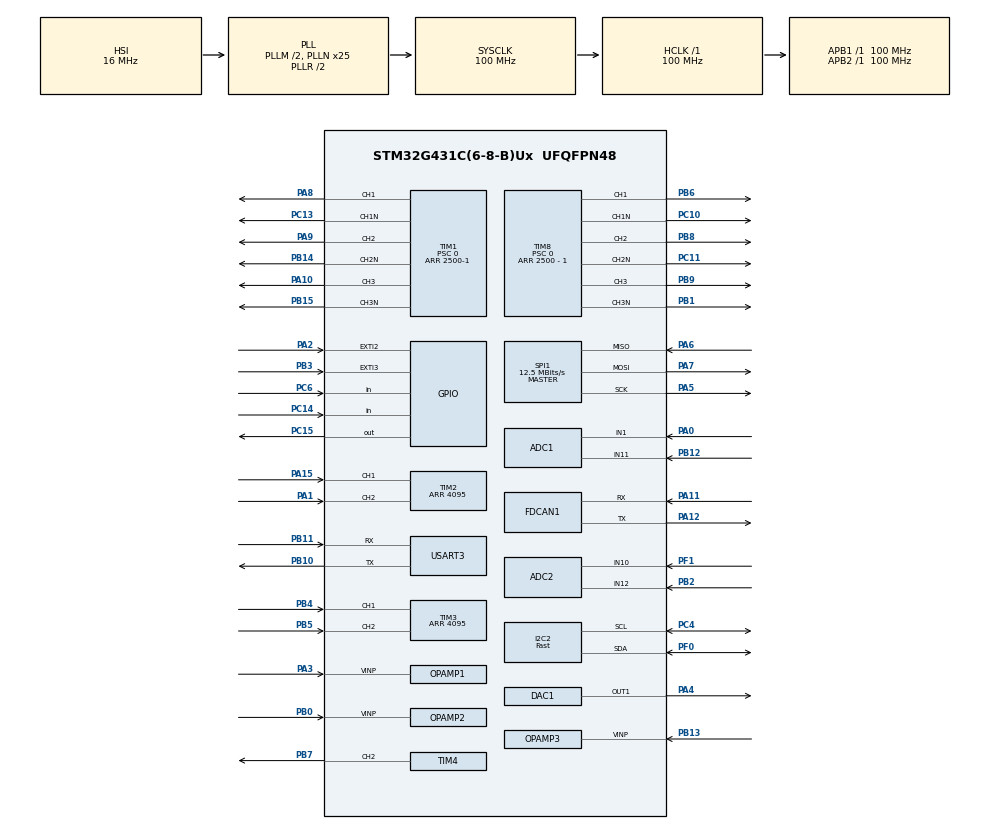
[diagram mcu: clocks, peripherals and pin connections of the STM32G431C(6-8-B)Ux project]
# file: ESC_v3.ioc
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ADC1.EnableInjectedConversion=ENABLE
ADC1.EnableRegularConversion=DISABLE
ADC1.ExternalTrigInjecConv=ADC_EXTERNALTRIGINJEC_T1_TRGO
ADC1.InjNumberOfConversion=1
ADC1.InjectedChannel-1\#ChannelInjectedConversion=ADC_CHANNEL_VOPAMP1
ADC1.InjectedOffsetNumber-1\#ChannelInjectedConversion=ADC_OFFSET_NONE
ADC1.InjectedRank-1\#ChannelInjectedConversion=1
ADC1.InjectedSamplingTime-1\#ChannelInjectedConversion=ADC_SAMPLETIME_2CYCLES_5
ADC1.Mode=ADC_DUALMODE_INJECSIMULT
ADC1.master=1
ADC2.EnableInjectedConversion=ENABLE
ADC2.EnableRegularConversion=DISABLE
ADC2.InjNumberOfConversion=2
ADC2.InjectedChannel-1\#ChannelInjectedConversion=ADC_CHANNEL_VOPAMP2
ADC2.InjectedChannel-2\#ChannelInjectedConversion=ADC_CHANNEL_VOPAMP3_ADC2
ADC2.InjectedOffsetNumber-1\#ChannelInjectedConversion=ADC_OFFSET_NONE
ADC2.InjectedOffsetNumber-2\#ChannelInjectedConversion=ADC_OFFSET_NONE
ADC2.InjectedRank-1\#ChannelInjectedConversion=1
ADC2.InjectedRank-2\#ChannelInjectedConversion=2
ADC2.InjectedSamplingTime-1\#ChannelInjectedConversion=ADC_SAMPLETIME_2CYCLES_5
ADC2.InjectedSamplingTime-2\#ChannelInjectedConversion=ADC_SAMPLETIME_2CYCLES_5
ADC2.Mode=ADC_DUALMODE_INJECSIMULT
Dma.Request0=TIM4_CH2
Dma.Request1=SPI1_TX
Dma.Request2=SPI1_RX
Dma.SPI1_RX.2.Direction=DMA_PERIPH_TO_MEMORY
Dma.SPI1_RX.2.EventEnable=DISABLE
Dma.SPI1_RX.2.Instance=DMA1_Channel3
Dma.SPI1_RX.2.MemDataAlignment=DMA_MDATAALIGN_BYTE
Dma.SPI1_RX.2.MemInc=DMA_MINC_ENABLE
Dma.SPI1_RX.2.Mode=DMA_NORMAL
Dma.SPI1_RX.2.PeriphDataAlignment=DMA_PDATAALIGN_BYTE
Dma.SPI1_RX.2.PeriphInc=DMA_PINC_DISABLE
Dma.SPI1_RX.2.Polarity=HAL_DMAMUX_REQ_GEN_RISING
Dma.SPI1_RX.2.Priority=DMA_PRIORITY_LOW
Dma.SPI1_RX.2.RequestNumber=1
Dma.SPI1_RX.2.SignalID=NONE
Dma.SPI1_RX.2.SyncEnable=DISABLE
Dma.SPI1_RX.2.SyncPolarity=HAL_DMAMUX_SYNC_NO_EVENT
Dma.SPI1_RX.2.SyncRequestNumber=1
Dma.SPI1_RX.2.SyncSignalID=NONE
Dma.SPI1_TX.1.Direction=DMA_MEMORY_TO_PERIPH
Dma.SPI1_TX.1.EventEnable=DISABLE
Dma.SPI1_TX.1.Instance=DMA1_Channel2
Dma.SPI1_TX.1.MemDataAlignment=DMA_MDATAALIGN_BYTE
Dma.SPI1_TX.1.MemInc=DMA_MINC_ENABLE
Dma.SPI1_TX.1.Mode=DMA_NORMAL
Dma.SPI1_TX.1.PeriphDataAlignment=DMA_PDATAALIGN_BYTE
Dma.SPI1_TX.1.PeriphInc=DMA_PINC_DISABLE
Dma.SPI1_TX.1.Polarity=HAL_DMAMUX_REQ_GEN_RISING
Dma.SPI1_TX.1.Priority=DMA_PRIORITY_LOW
Dma.SPI1_TX.1.RequestNumber=1
Dma.SPI1_TX.1.SignalID=NONE
Dma.SPI1_TX.1.SyncEnable=DISABLE
Dma.SPI1_TX.1.SyncPolarity=HAL_DMAMUX_SYNC_NO_EVENT
Dma.SPI1_TX.1.SyncRequestNumber=1
Dma.SPI1_TX.1.SyncSignalID=NONE
Dma.TIM4_CH2.0.Direction=DMA_MEMORY_TO_PERIPH
Dma.TIM4_CH2.0.EventEnable=DISABLE
Dma.TIM4_CH2.0.Instance=DMA1_Channel1
Dma.TIM4_CH2.0.MemDataAlignment=DMA_MDATAALIGN_HALFWORD
Dma.TIM4_CH2.0.MemInc=DMA_MINC_ENABLE
Dma.TIM4_CH2.0.Mode=DMA_NORMAL
Dma.TIM4_CH2.0.PeriphDataAlignment=DMA_PDATAALIGN_HALFWORD
Dma.TIM4_CH2.0.PeriphInc=DMA_PINC_DISABLE
Dma.TIM4_CH2.0.Polarity=HAL_DMAMUX_REQ_GEN_RISING
Dma.TIM4_CH2.0.Priority=DMA_PRIORITY_LOW
Dma.TIM4_CH2.0.RequestNumber=1
Dma.TIM4_CH2.0.SignalID=NONE
Dma.TIM4_CH2.0.SyncEnable=DISABLE
Dma.TIM4_CH2.0.SyncPolarity=HAL_DMAMUX_SYNC_NO_EVENT
Dma.TIM4_CH2.0.SyncRequestNumber=1
Dma.TIM4_CH2.0.SyncSignalID=NONE
FDCAN1.CalculateBaudRateNominal=1000000
FDCAN1.CalculateTimeBitNominal=1000
FDCAN1.CalculateTimeQuantumNominal=10.0
FDCAN1.NominalPrescaler=1
FDCAN1.NominalTimeSeg1=80
FDCAN1.NominalTimeSeg2=19
I2C2.I2C_Speed_Mode=I2C_Fast
I2C2.Timing=0x10911A50
Mcu.Family=STM32G4
Mcu.Name=STM32G431C(6-8-B)Ux
Mcu.Package=UFQFPN48
NVIC.ADC1_2_IRQn=true\:0\:0\:false\:false\:true\:true\:true\:true
NVIC.DMA1_Channel1_IRQn=true\:0\:0\:false\:false\:true\:false\:true\:true
NVIC.DMA1_Channel2_IRQn=true\:0\:0\:false\:false\:true\:false\:true\:true
NVIC.DMA1_Channel3_IRQn=true\:0\:0\:false\:false\:true\:false\:true\:true
NVIC.EXTI2_IRQn=true\:0\:0\:false\:false\:true\:true\:true\:true
NVIC.EXTI3_IRQn=true\:0\:0\:false\:false\:true\:true\:true\:true
NVIC.FMAC_IRQn=true\:0\:0\:false\:false\:true\:true\:true\:true
NVIC.PriorityGroup=NVIC_PRIORITYGROUP_4
NVIC.SPI1_IRQn=true\:0\:0\:false\:false\:true\:true\:true\:true
NVIC.TIM1_UP_TIM16_IRQn=true\:0\:0\:false\:false\:true\:true\:true\:true
NVIC.TIM6_DAC_IRQn=true\:0\:0\:false\:false\:true\:true\:true\:true
NVIC.TIM7_IRQn=true\:0\:0\:false\:false\:true\:true\:true\:true
OPAMP1.PgaGain=OPAMP_PGA_GAIN_32_OR_MINUS_31
OPAMP2.PgaGain=OPAMP_PGA_GAIN_32_OR_MINUS_31
OPAMP3.PgaGain=OPAMP_PGA_GAIN_32_OR_MINUS_31
PA0.Mode=IN1-Single-Ended
PA0.Signal=ADC1_IN1
PA1.Signal=S_TIM2_CH2
PA10.Signal=S_TIM1_CH3
PA11.Mode=FDCAN_Activate
PA11.Signal=FDCAN1_RX
PA12.Mode=FDCAN_Activate
PA12.Signal=FDCAN1_TX
PA13.Mode=Serial_Wire
PA13.Signal=SYS_JTMS-SWDIO
PA14.Mode=Serial_Wire
PA14.Signal=SYS_JTCK-SWCLK
PA15.Signal=S_TIM2_CH1
PA2.Signal=SharedStack_PA2
PA2.Stacked=true
PA3.Mode=PGA_Internally_Connected
PA3.Signal=OPAMP1_VINP
PA4.Signal=COMP_DAC11_group
PA5.Mode=Full_Duplex_Master
PA5.Signal=SPI1_SCK
PA6.Mode=Full_Duplex_Master
PA6.Signal=SPI1_MISO
PA7.Mode=Full_Duplex_Master
PA7.Signal=SPI1_MOSI
PA8.Signal=S_TIM1_CH1
PA9.Signal=S_TIM1_CH2
PB0.Mode=PGA_Internally_Connected
PB0.Signal=OPAMP2_VINP
PB1.Mode=PWM Generation3 CH3 CH3N
PB1.Signal=TIM8_CH3N
PB10.Mode=Asynchronous
PB10.Signal=USART3_TX
PB11.Mode=Asynchronous
PB11.Signal=USART3_RX
PB12.Mode=IN11-Single-Ended
PB12.Signal=ADC1_IN11
PB13.Mode=PGA_Internally_Connected
PB13.Signal=OPAMP3_VINP
PB14.Mode=PWM Generation2 CH2 CH2N
PB14.Signal=TIM1_CH2N
PB15.Mode=PWM Generation3 CH3 CH3N
PB15.Signal=TIM1_CH3N
PB2.Mode=IN12-Single-Ended
PB2.Signal=ADC2_IN12
PB3.Signal=SharedStack_PB3
PB3.Stacked=true
PB4.Signal=SharedStack_PB4
PB4.Stacked=true
PB5.Signal=S_TIM3_CH2
PB5.Stacked=true
PB6.Signal=S_TIM8_CH1
PB7.Signal=S_TIM4_CH2
PB8-BOOT0.Signal=S_TIM8_CH2
PB9.Signal=S_TIM8_CH3
PC10.Mode=PWM Generation1 CH1 CH1N
PC10.Signal=TIM8_CH1N
PC11.Mode=PWM Generation2 CH2 CH2N
PC11.Signal=TIM8_CH2N
PC13.Mode=PWM Generation1 CH1 CH1N
PC13.Signal=TIM1_CH1N
PC14-OSC32_IN.Signal=GPIO_Input
PC15-OSC32_OUT.Signal=GPIO_Output
PC4.Mode=I2C
PC4.Signal=I2C2_SCL
PC6.Signal=GPIO_Input
PF0-OSC_IN.Mode=I2C
PF0-OSC_IN.Signal=I2C2_SDA
PF1-OSC_OUT.Mode=IN10-Single-Ended
PF1-OSC_OUT.Signal=ADC2_IN10
ProjectManager.HeapSize=0x200
ProjectManager.StackSize=0x400
ProjectManager.TargetToolchain=CMake
RCC.ADC12Freq_Value=100000000
RCC.AHBFreq_Value=100000000
RCC.APB1Freq_Value=100000000
RCC.APB1TimFreq_Value=100000000
RCC.APB2Freq_Value=100000000
RCC.APB2TimFreq_Value=100000000
RCC.CortexFreq_Value=100000000
RCC.EXTERNAL_CLOCK_VALUE=12288000
RCC.HCLKFreq_Value=100000000
RCC.HSE_VALUE=8000000
RCC.HSI48_VALUE=48000000
RCC.HSI_VALUE=16000000
RCC.LSE_VALUE=32768
RCC.PLLM=RCC_PLLM_DIV2
RCC.PLLN=25
RCC.SYSCLKFreq_VALUE=100000000
RCC.SYSCLKSource=RCC_SYSCLKSOURCE_PLLCLK
RCC.USBFreq_Value=100000000
RCC.VCOOutputFreq_Value=200000000
SH.COMP_DAC11_group.0=DAC1_OUT1,DAC_OUT1
SH.S_TIM1_CH1.0=TIM1_CH1,PWM Generation1 CH1 CH1N
SH.S_TIM1_CH2.0=TIM1_CH2,PWM Generation2 CH2 CH2N
SH.S_TIM1_CH3.0=TIM1_CH3,PWM Generation3 CH3 CH3N
SH.S_TIM2_CH1.0=TIM2_CH1,Encoder_Interface
SH.S_TIM2_CH2.0=TIM2_CH2,Encoder_Interface
SH.S_TIM3_CH2.0=TIM3_CH2,Encoder_Interface
SH.S_TIM4_CH2.0=TIM4_CH2,PWM Generation2 CH2
SH.S_TIM8_CH1.0=TIM8_CH1,PWM Generation1 CH1 CH1N
SH.S_TIM8_CH2.0=TIM8_CH2,PWM Generation2 CH2 CH2N
SH.S_TIM8_CH3.0=TIM8_CH3,PWM Generation3 CH3 CH3N
SH.SharedStack_PA2.0=TIM2_CH3
SH.SharedStack_PA2.1=GPIO_EXTI2
SH.SharedStack_PB3.0=GPIO_EXTI3
SH.SharedStack_PB3.1=SPI3_SCK
SH.SharedStack_PB4.0=SPI3_MISO
SH.SharedStack_PB4.1=TIM3_CH1,Encoder_Interface
SPI1.BaudRatePrescaler=SPI_BAUDRATEPRESCALER_8
SPI1.CLKPhase=SPI_PHASE_2EDGE
SPI1.CalculateBaudRate=12.5 MBits/s
SPI1.DataSize=SPI_DATASIZE_8BIT
SPI1.Direction=SPI_DIRECTION_2LINES
SPI1.Mode=SPI_MODE_MASTER
SPI1.VirtualType=VM_MASTER
TIM1.Channel-PWM\ Generation1\ CH1\ CH1N=TIM_CHANNEL_1
TIM1.Channel-PWM\ Generation2\ CH2\ CH2N=TIM_CHANNEL_2
TIM1.Channel-PWM\ Generation3\ CH3\ CH3N=TIM_CHANNEL_3
TIM1.CounterMode=TIM_COUNTERMODE_CENTERALIGNED1
TIM1.OCMode_PWM-PWM\ Generation1\ CH1\ CH1N=TIM_OCMODE_PWM2
TIM1.OCMode_PWM-PWM\ Generation2\ CH2\ CH2N=TIM_OCMODE_PWM2
TIM1.OCMode_PWM-PWM\ Generation3\ CH3\ CH3N=TIM_OCMODE_PWM2
TIM1.PeriodNoDither=2500-1
TIM1.Prescaler=0
TIM1.RepetitionCounter=1
TIM1.TIM_MasterOutputTrigger=TIM_TRGO_UPDATE
TIM2.PeriodNoDither=4095
TIM3.PeriodNoDither=4095
TIM4.Channel-PWM\ Generation2\ CH2=TIM_CHANNEL_2
TIM4.PeriodNoDither=149
TIM6.PeriodNoDither=9999
TIM6.Prescaler=9999
TIM7.PeriodNoDither=999
TIM7.Prescaler=9900
TIM8.Channel-PWM\ Generation1\ CH1\ CH1N=TIM_CHANNEL_1
TIM8.Channel-PWM\ Generation2\ CH2\ CH2N=TIM_CHANNEL_2
TIM8.Channel-PWM\ Generation3\ CH3\ CH3N=TIM_CHANNEL_3
TIM8.PeriodNoDither=2500 - 1
TIM8.Prescaler=0
USART3.VirtualMode-Asynchronous=VM_ASYNC
VP_ADC1_OPAMP_INTERNAL1.Mode=IN-OPAMP1
VP_ADC2_OPAMP_INTERNAL2.Mode=IN-OPAMP2
VP_ADC2_OPAMP_INTERNAL3.Mode=IN-OPAMP3
VP_CORDIC_VS_CORDIC.Mode=CORDIC_Activate
VP_FMAC_VS_FMAC.Mode=FMAC_Activate
VP_SYS_VS_DBSignals.Mode=DisableDeadBatterySignals
VP_TIM17_VS_ClockSourceINT.Mode=Enable_Timer
VP_TIM6_VS_ClockSourceINT.Mode=Enable_Timer
VP_TIM7_VS_ClockSourceINT.Mode=Enable_Timer
board=custom

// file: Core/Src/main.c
/* USER CODE BEGIN Header */
/**
  ******************************************************************************
  * @file           : main.c
  * @brief          : Main program body
  ******************************************************************************
  * @attention
  *
  * Copyright (c) 2026 STMicroelectronics.
  * All rights reserved.
  *
  * This software is licensed under terms that can be found in the LICENSE file
  * in the root directory of this software component.
  * If no LICENSE file comes with this software, it is provided AS-IS.
  *
  ******************************************************************************
  */
/* USER CODE END Header */
#include "main.h"

ADC_HandleTypeDef hadc1;
ADC_HandleTypeDef hadc2;

CORDIC_HandleTypeDef hcordic;

DAC_HandleTypeDef hdac1;

FDCAN_HandleTypeDef hfdcan1;

FMAC_HandleTypeDef hfmac;

I2C_HandleTypeDef hi2c2;

OPAMP_HandleTypeDef hopamp1;
OPAMP_HandleTypeDef hopamp2;
OPAMP_HandleTypeDef hopamp3;

SPI_HandleTypeDef hspi1;
DMA_HandleTypeDef hdma_spi1_tx;
DMA_HandleTypeDef hdma_spi1_rx;

TIM_HandleTypeDef htim1;
TIM_HandleTypeDef htim2;
TIM_HandleTypeDef htim3;
TIM_HandleTypeDef htim4;
TIM_HandleTypeDef htim6;
TIM_HandleTypeDef htim7;
TIM_HandleTypeDef htim8;
TIM_HandleTypeDef htim17;
DMA_HandleTypeDef hdma_tim4_ch2;

UART_HandleTypeDef huart3;

void SystemClock_Config(void);
static void MX_GPIO_Init(void);
static void MX_DMA_Init(void);
static void MX_FDCAN1_Init(void);
static void MX_TIM1_Init(void);
static void MX_TIM2_Init(void);
static void MX_TIM8_Init(void);
static void MX_TIM4_Init(void);
static void MX_I2C2_Init(void);
static void MX_OPAMP1_Init(void);
static void MX_OPAMP2_Init(void);
static void MX_OPAMP3_Init(void);
static void MX_USART3_UART_Init(void);
static void MX_ADC2_Init(void);
static void MX_CORDIC_Init(void);
static void MX_FMAC_Init(void);
static void MX_TIM6_Init(void);
static void MX_TIM7_Init(void);
static void MX_ADC1_Init(void);
static void MX_SPI1_Init(void);
static void MX_DAC1_Init(void);
static void MX_TIM3_Init(void);
static void MX_TIM17_Init(void);

int main(void)
{

  /* MCU Configuration--------------------------------------------------------*/

  /* Reset of all peripherals, Initializes the Flash interface and the Systick. */
  HAL_Init();

  /* Configure the system clock */
  SystemClock_Config();

  /* Initialize all configured peripherals */
  MX_GPIO_Init();
  MX_DMA_Init();
  MX_FDCAN1_Init();
  MX_TIM1_Init();
  MX_TIM2_Init();
  MX_TIM8_Init();
  MX_TIM4_Init();
  MX_I2C2_Init();
  MX_OPAMP1_Init();
  MX_OPAMP2_Init();
  MX_OPAMP3_Init();
  MX_USART3_UART_Init();
  MX_ADC2_Init();
  MX_CORDIC_Init();
  MX_FMAC_Init();
  MX_TIM6_Init();
  MX_TIM7_Init();
  MX_ADC1_Init();
  MX_SPI1_Init();
  MX_DAC1_Init();
  MX_TIM3_Init();
  MX_TIM17_Init();

  /* Infinite loop */
  /* USER CODE BEGIN WHILE */
  extern void setup(void);
  setup();
  while (1)
  {
    extern void loop(void);
    loop();
    /* USER CODE END WHILE */

  }
}

void SystemClock_Config(void)
{
  RCC_OscInitTypeDef RCC_OscInitStruct = {0};
  RCC_ClkInitTypeDef RCC_ClkInitStruct = {0};

  /** Configure the main internal regulator output voltage
  */
  HAL_PWREx_ControlVoltageScaling(PWR_REGULATOR_VOLTAGE_SCALE1);

  /** Initializes the RCC Oscillators according to the specified parameters
  * in the RCC_OscInitTypeDef structure.
  */
  RCC_OscInitStruct.OscillatorType = RCC_OSCILLATORTYPE_HSI;
  RCC_OscInitStruct.HSIState = RCC_HSI_ON;
  RCC_OscInitStruct.HSICalibrationValue = RCC_HSICALIBRATION_DEFAULT;
  RCC_OscInitStruct.PLL.PLLState = RCC_PLL_ON;
  RCC_OscInitStruct.PLL.PLLSource = RCC_PLLSOURCE_HSI;
  RCC_OscInitStruct.PLL.PLLM = RCC_PLLM_DIV2;
  RCC_OscInitStruct.PLL.PLLN = 25;
  RCC_OscInitStruct.PLL.PLLP = RCC_PLLP_DIV2;
  RCC_OscInitStruct.PLL.PLLQ = RCC_PLLQ_DIV2;
  RCC_OscInitStruct.PLL.PLLR = RCC_PLLR_DIV2;
  if (HAL_RCC_OscConfig(&RCC_OscInitStruct) != HAL_OK)
  {
    Error_Handler();
  }

  /** Initializes the CPU, AHB and APB buses clocks
  */
  RCC_ClkInitStruct.ClockType = RCC_CLOCKTYPE_HCLK|RCC_CLOCKTYPE_SYSCLK
                              |RCC_CLOCKTYPE_PCLK1|RCC_CLOCKTYPE_PCLK2;
  RCC_ClkInitStruct.SYSCLKSource = RCC_SYSCLKSOURCE_PLLCLK;
  RCC_ClkInitStruct.AHBCLKDivider = RCC_SYSCLK_DIV1;
  RCC_ClkInitStruct.APB1CLKDivider = RCC_HCLK_DIV1;
  RCC_ClkInitStruct.APB2CLKDivider = RCC_HCLK_DIV1;

  if (HAL_RCC_ClockConfig(&RCC_ClkInitStruct, FLASH_LATENCY_3) != HAL_OK)
  {
    Error_Handler();
  }
}

static void MX_ADC1_Init(void)
{

  ADC_MultiModeTypeDef multimode = {0};
  ADC_InjectionConfTypeDef sConfigInjected = {0};

  /** Common config
  */
  hadc1.Instance = ADC1;
  hadc1.Init.ClockPrescaler = ADC_CLOCK_SYNC_PCLK_DIV2;
  hadc1.Init.Resolution = ADC_RESOLUTION_12B;
  hadc1.Init.DataAlign = ADC_DATAALIGN_RIGHT;
  hadc1.Init.GainCompensation = 0;
  hadc1.Init.ScanConvMode = ADC_SCAN_DISABLE;
  hadc1.Init.EOCSelection = ADC_EOC_SINGLE_CONV;
  hadc1.Init.LowPowerAutoWait = DISABLE;
  hadc1.Init.ContinuousConvMode = DISABLE;
  hadc1.Init.NbrOfConversion = 1;
  hadc1.Init.DiscontinuousConvMode = DISABLE;
  hadc1.Init.DMAContinuousRequests = DISABLE;
  hadc1.Init.Overrun = ADC_OVR_DATA_PRESERVED;
  hadc1.Init.OversamplingMode = DISABLE;
  if (HAL_ADC_Init(&hadc1) != HAL_OK)
  {
    Error_Handler();
  }

  /** Configure the ADC multi-mode
  */
  multimode.Mode = ADC_DUALMODE_INJECSIMULT;
  multimode.DMAAccessMode = ADC_DMAACCESSMODE_DISABLED;
  multimode.TwoSamplingDelay = ADC_TWOSAMPLINGDELAY_1CYCLE;
  if (HAL_ADCEx_MultiModeConfigChannel(&hadc1, &multimode) != HAL_OK)
  {
    Error_Handler();
  }

  /** Configure Injected Channel
  */
  sConfigInjected.InjectedChannel = ADC_CHANNEL_VOPAMP1;
  sConfigInjected.InjectedRank = ADC_INJECTED_RANK_1;
  sConfigInjected.InjectedSamplingTime = ADC_SAMPLETIME_2CYCLES_5;
  sConfigInjected.InjectedSingleDiff = ADC_SINGLE_ENDED;
  sConfigInjected.InjectedOffsetNumber = ADC_OFFSET_NONE;
  sConfigInjected.InjectedOffset = 0;
  sConfigInjected.InjectedNbrOfConversion = 1;
  sConfigInjected.InjectedDiscontinuousConvMode = DISABLE;
  sConfigInjected.AutoInjectedConv = DISABLE;
  sConfigInjected.QueueInjectedContext = DISABLE;
  sConfigInjected.ExternalTrigInjecConv = ADC_EXTERNALTRIGINJEC_T1_TRGO;
  sConfigInjected.ExternalTrigInjecConvEdge = ADC_EXTERNALTRIGINJECCONV_EDGE_RISING;
  sConfigInjected.InjecOversamplingMode = DISABLE;
  if (HAL_ADCEx_InjectedConfigChannel(&hadc1, &sConfigInjected) != HAL_OK)
  {
    Error_Handler();
  }

}

static void MX_ADC2_Init(void)
{

  ADC_InjectionConfTypeDef sConfigInjected = {0};

  /** Common config
  */
  hadc2.Instance = ADC2;
  hadc2.Init.ClockPrescaler = ADC_CLOCK_SYNC_PCLK_DIV2;
  hadc2.Init.Resolution = ADC_RESOLUTION_12B;
  hadc2.Init.DataAlign = ADC_DATAALIGN_RIGHT;
  hadc2.Init.GainCompensation = 0;
  hadc2.Init.ScanConvMode = ADC_SCAN_ENABLE;
  hadc2.Init.EOCSelection = ADC_EOC_SINGLE_CONV;
  hadc2.Init.LowPowerAutoWait = DISABLE;
  hadc2.Init.ContinuousConvMode = DISABLE;
  hadc2.Init.NbrOfConversion = 1;
  hadc2.Init.DiscontinuousConvMode = DISABLE;
  hadc2.Init.DMAContinuousRequests = DISABLE;
  hadc2.Init.Overrun = ADC_OVR_DATA_PRESERVED;
  hadc2.Init.OversamplingMode = DISABLE;
  if (HAL_ADC_Init(&hadc2) != HAL_OK)
  {
    Error_Handler();
  }

  /** Configure Injected Channel
  */
  sConfigInjected.InjectedChannel = ADC_CHANNEL_VOPAMP2;
  sConfigInjected.InjectedRank = ADC_INJECTED_RANK_1;
  sConfigInjected.InjectedSamplingTime = ADC_SAMPLETIME_2CYCLES_5;
  sConfigInjected.InjectedSingleDiff = ADC_SINGLE_ENDED;
  sConfigInjected.InjectedOffsetNumber = ADC_OFFSET_NONE;
  sConfigInjected.InjectedOffset = 0;
  sConfigInjected.InjectedNbrOfConversion = 2;
  sConfigInjected.InjectedDiscontinuousConvMode = DISABLE;
  sConfigInjected.AutoInjectedConv = DISABLE;
  sConfigInjected.QueueInjectedContext = DISABLE;
  sConfigInjected.InjecOversamplingMode = DISABLE;
  if (HAL_ADCEx_InjectedConfigChannel(&hadc2, &sConfigInjected) != HAL_OK)
  {
    Error_Handler();
  }

  /** Configure Injected Channel
  */
  sConfigInjected.InjectedChannel = ADC_CHANNEL_VOPAMP3_ADC2;
  sConfigInjected.InjectedRank = ADC_INJECTED_RANK_2;
  if (HAL_ADCEx_InjectedConfigChannel(&hadc2, &sConfigInjected) != HAL_OK)
  {
    Error_Handler();
  }

}

static void MX_CORDIC_Init(void)
{

  hcordic.Instance = CORDIC;
  if (HAL_CORDIC_Init(&hcordic) != HAL_OK)
  {
    Error_Handler();
  }

}

static void MX_DAC1_Init(void)
{

  DAC_ChannelConfTypeDef sConfig = {0};

  /** DAC Initialization
  */
  hdac1.Instance = DAC1;
  if (HAL_DAC_Init(&hdac1) != HAL_OK)
  {
    Error_Handler();
  }

  /** DAC channel OUT1 config
  */
  sConfig.DAC_HighFrequency = DAC_HIGH_FREQUENCY_INTERFACE_MODE_AUTOMATIC;
  sConfig.DAC_DMADoubleDataMode = DISABLE;
  sConfig.DAC_SignedFormat = DISABLE;
  sConfig.DAC_SampleAndHold = DAC_SAMPLEANDHOLD_DISABLE;
  sConfig.DAC_Trigger = DAC_TRIGGER_NONE;
  sConfig.DAC_Trigger2 = DAC_TRIGGER_NONE;
  sConfig.DAC_OutputBuffer = DAC_OUTPUTBUFFER_ENABLE;
  sConfig.DAC_ConnectOnChipPeripheral = DAC_CHIPCONNECT_EXTERNAL;
  sConfig.DAC_UserTrimming = DAC_TRIMMING_FACTORY;
  if (HAL_DAC_ConfigChannel(&hdac1, &sConfig, DAC_CHANNEL_1) != HAL_OK)
  {
    Error_Handler();
  }

}

static void MX_FDCAN1_Init(void)
{

  hfdcan1.Instance = FDCAN1;
  hfdcan1.Init.ClockDivider = FDCAN_CLOCK_DIV1;
  hfdcan1.Init.FrameFormat = FDCAN_FRAME_CLASSIC;
  hfdcan1.Init.Mode = FDCAN_MODE_NORMAL;
  hfdcan1.Init.AutoRetransmission = DISABLE;
  hfdcan1.Init.TransmitPause = DISABLE;
  hfdcan1.Init.ProtocolException = DISABLE;
  hfdcan1.Init.NominalPrescaler = 1;
  hfdcan1.Init.NominalSyncJumpWidth = 1;
  hfdcan1.Init.NominalTimeSeg1 = 80;
  hfdcan1.Init.NominalTimeSeg2 = 19;
  hfdcan1.Init.DataPrescaler = 1;
  hfdcan1.Init.DataSyncJumpWidth = 1;
  hfdcan1.Init.DataTimeSeg1 = 1;
  hfdcan1.Init.DataTimeSeg2 = 1;
  hfdcan1.Init.StdFiltersNbr = 0;
  hfdcan1.Init.ExtFiltersNbr = 0;
  hfdcan1.Init.TxFifoQueueMode = FDCAN_TX_FIFO_OPERATION;
  if (HAL_FDCAN_Init(&hfdcan1) != HAL_OK)
  {
    Error_Handler();
  }

}

static void MX_FMAC_Init(void)
{

  hfmac.Instance = FMAC;
  if (HAL_FMAC_Init(&hfmac) != HAL_OK)
  {
    Error_Handler();
  }

}

static void MX_I2C2_Init(void)
{

  hi2c2.Instance = I2C2;
  hi2c2.Init.Timing = 0x10911A50;
  hi2c2.Init.OwnAddress1 = 0;
  hi2c2.Init.AddressingMode = I2C_ADDRESSINGMODE_7BIT;
  hi2c2.Init.DualAddressMode = I2C_DUALADDRESS_DISABLE;
  hi2c2.Init.OwnAddress2 = 0;
  hi2c2.Init.OwnAddress2Masks = I2C_OA2_NOMASK;
  hi2c2.Init.GeneralCallMode = I2C_GENERALCALL_DISABLE;
  hi2c2.Init.NoStretchMode = I2C_NOSTRETCH_DISABLE;
  if (HAL_I2C_Init(&hi2c2) != HAL_OK)
  {
    Error_Handler();
  }

  /** Configure Analogue filter
  */
  if (HAL_I2CEx_ConfigAnalogFilter(&hi2c2, I2C_ANALOGFILTER_ENABLE) != HAL_OK)
  {
    Error_Handler();
  }

  /** Configure Digital filter
  */
  if (HAL_I2CEx_ConfigDigitalFilter(&hi2c2, 0) != HAL_OK)
  {
    Error_Handler();
  }

}

static void MX_OPAMP1_Init(void)
{

  hopamp1.Instance = OPAMP1;
  hopamp1.Init.PowerMode = OPAMP_POWERMODE_NORMALSPEED;
  hopamp1.Init.Mode = OPAMP_PGA_MODE;
  hopamp1.Init.NonInvertingInput = OPAMP_NONINVERTINGINPUT_IO1;
  hopamp1.Init.InternalOutput = ENABLE;
  hopamp1.Init.TimerControlledMuxmode = OPAMP_TIMERCONTROLLEDMUXMODE_DISABLE;
  hopamp1.Init.PgaConnect = OPAMP_PGA_CONNECT_INVERTINGINPUT_NO;
  hopamp1.Init.PgaGain = OPAMP_PGA_GAIN_32_OR_MINUS_31;
  hopamp1.Init.UserTrimming = OPAMP_TRIMMING_FACTORY;
  if (HAL_OPAMP_Init(&hopamp1) != HAL_OK)
  {
    Error_Handler();
  }

}

static void MX_OPAMP2_Init(void)
{

  hopamp2.Instance = OPAMP2;
  hopamp2.Init.PowerMode = OPAMP_POWERMODE_NORMALSPEED;
  hopamp2.Init.Mode = OPAMP_PGA_MODE;
  hopamp2.Init.NonInvertingInput = OPAMP_NONINVERTINGINPUT_IO2;
  hopamp2.Init.InternalOutput = ENABLE;
  hopamp2.Init.TimerControlledMuxmode = OPAMP_TIMERCONTROLLEDMUXMODE_DISABLE;
  hopamp2.Init.PgaConnect = OPAMP_PGA_CONNECT_INVERTINGINPUT_NO;
  hopamp2.Init.PgaGain = OPAMP_PGA_GAIN_32_OR_MINUS_31;
  hopamp2.Init.UserTrimming = OPAMP_TRIMMING_FACTORY;
  if (HAL_OPAMP_Init(&hopamp2) != HAL_OK)
  {
    Error_Handler();
  }

}

static void MX_OPAMP3_Init(void)
{

  hopamp3.Instance = OPAMP3;
  hopamp3.Init.PowerMode = OPAMP_POWERMODE_NORMALSPEED;
  hopamp3.Init.Mode = OPAMP_PGA_MODE;
  hopamp3.Init.NonInvertingInput = OPAMP_NONINVERTINGINPUT_IO1;
  hopamp3.Init.InternalOutput = ENABLE;
  hopamp3.Init.TimerControlledMuxmode = OPAMP_TIMERCONTROLLEDMUXMODE_DISABLE;
  hopamp3.Init.PgaConnect = OPAMP_PGA_CONNECT_INVERTINGINPUT_NO;
  hopamp3.Init.PgaGain = OPAMP_PGA_GAIN_32_OR_MINUS_31;
  hopamp3.Init.UserTrimming = OPAMP_TRIMMING_FACTORY;
  if (HAL_OPAMP_Init(&hopamp3) != HAL_OK)
  {
    Error_Handler();
  }

}

static void MX_SPI1_Init(void)
{

  /* SPI1 parameter configuration*/
  hspi1.Instance = SPI1;
  hspi1.Init.Mode = SPI_MODE_MASTER;
  hspi1.Init.Direction = SPI_DIRECTION_2LINES;
  hspi1.Init.DataSize = SPI_DATASIZE_8BIT;
  hspi1.Init.CLKPolarity = SPI_POLARITY_LOW;
  hspi1.Init.CLKPhase = SPI_PHASE_2EDGE;
  hspi1.Init.NSS = SPI_NSS_SOFT;
  hspi1.Init.BaudRatePrescaler = SPI_BAUDRATEPRESCALER_8;
  hspi1.Init.FirstBit = SPI_FIRSTBIT_MSB;
  hspi1.Init.TIMode = SPI_TIMODE_DISABLE;
  hspi1.Init.CRCCalculation = SPI_CRCCALCULATION_DISABLE;
  hspi1.Init.CRCPolynomial = 7;
  hspi1.Init.CRCLength = SPI_CRC_LENGTH_DATASIZE;
  hspi1.Init.NSSPMode = SPI_NSS_PULSE_DISABLE;
  if (HAL_SPI_Init(&hspi1) != HAL_OK)
  {
    Error_Handler();
  }

}

static void MX_TIM1_Init(void)
{

  TIM_MasterConfigTypeDef sMasterConfig = {0};
  TIM_OC_InitTypeDef sConfigOC = {0};
  TIM_BreakDeadTimeConfigTypeDef sBreakDeadTimeConfig = {0};

  htim1.Instance = TIM1;
  htim1.Init.Prescaler = 0;
  htim1.Init.CounterMode = TIM_COUNTERMODE_CENTERALIGNED1;
  htim1.Init.Period = 2499;
  htim1.Init.ClockDivision = TIM_CLOCKDIVISION_DIV1;
  htim1.Init.RepetitionCounter = 1;
  htim1.Init.AutoReloadPreload = TIM_AUTORELOAD_PRELOAD_DISABLE;
  if (HAL_TIM_PWM_Init(&htim1) != HAL_OK)
  {
    Error_Handler();
  }
  sMasterConfig.MasterOutputTrigger = TIM_TRGO_UPDATE;
  sMasterConfig.MasterOutputTrigger2 = TIM_TRGO2_RESET;
  sMasterConfig.MasterSlaveMode = TIM_MASTERSLAVEMODE_DISABLE;
  if (HAL_TIMEx_MasterConfigSynchronization(&htim1, &sMasterConfig) != HAL_OK)
  {
    Error_Handler();
  }
  sConfigOC.OCMode = TIM_OCMODE_PWM2;
  sConfigOC.Pulse = 0;
  sConfigOC.OCPolarity = TIM_OCPOLARITY_HIGH;
  sConfigOC.OCNPolarity = TIM_OCNPOLARITY_HIGH;
  sConfigOC.OCFastMode = TIM_OCFAST_DISABLE;
  sConfigOC.OCIdleState = TIM_OCIDLESTATE_RESET;
  sConfigOC.OCNIdleState = TIM_OCNIDLESTATE_RESET;
  if (HAL_TIM_PWM_ConfigChannel(&htim1, &sConfigOC, TIM_CHANNEL_1) != HAL_OK)
  {
    Error_Handler();
  }
  if (HAL_TIM_PWM_ConfigChannel(&htim1, &sConfigOC, TIM_CHANNEL_2) != HAL_OK)
  {
    Error_Handler();
  }
  if (HAL_TIM_PWM_ConfigChannel(&htim1, &sConfigOC, TIM_CHANNEL_3) != HAL_OK)
  {
    Error_Handler();
  }
  sBreakDeadTimeConfig.OffStateRunMode = TIM_OSSR_DISABLE;
  sBreakDeadTimeConfig.OffStateIDLEMode = TIM_OSSI_DISABLE;
  sBreakDeadTimeConfig.LockLevel = TIM_LOCKLEVEL_OFF;
  sBreakDeadTimeConfig.DeadTime = 0;
  sBreakDeadTimeConfig.BreakState = TIM_BREAK_DISABLE;
  sBreakDeadTimeConfig.BreakPolarity = TIM_BREAKPOLARITY_HIGH;
  sBreakDeadTimeConfig.BreakFilter = 0;
  sBreakDeadTimeConfig.BreakAFMode = TIM_BREAK_AFMODE_INPUT;
  sBreakDeadTimeConfig.Break2State = TIM_BREAK2_DISABLE;
  sBreakDeadTimeConfig.Break2Polarity = TIM_BREAK2POLARITY_HIGH;
  sBreakDeadTimeConfig.Break2Filter = 0;
  sBreakDeadTimeConfig.Break2AFMode = TIM_BREAK_AFMODE_INPUT;
  sBreakDeadTimeConfig.AutomaticOutput = TIM_AUTOMATICOUTPUT_DISABLE;
  if (HAL_TIMEx_ConfigBreakDeadTime(&htim1, &sBreakDeadTimeConfig) != HAL_OK)
  {
    Error_Handler();
  }
  HAL_TIM_MspPostInit(&htim1);

}

static void MX_TIM2_Init(void)
{

  TIM_Encoder_InitTypeDef sConfig = {0};
  TIM_MasterConfigTypeDef sMasterConfig = {0};

  htim2.Instance = TIM2;
  htim2.Init.Prescaler = 0;
  htim2.Init.CounterMode = TIM_COUNTERMODE_UP;
  htim2.Init.Period = 4095;
  htim2.Init.ClockDivision = TIM_CLOCKDIVISION_DIV1;
  htim2.Init.AutoReloadPreload = TIM_AUTORELOAD_PRELOAD_DISABLE;
  sConfig.EncoderMode = TIM_ENCODERMODE_TI1;
  sConfig.IC1Polarity = TIM_ICPOLARITY_RISING;
  sConfig.IC1Selection = TIM_ICSELECTION_DIRECTTI;
  sConfig.IC1Prescaler = TIM_ICPSC_DIV1;
  sConfig.IC1Filter = 0;
  sConfig.IC2Polarity = TIM_ICPOLARITY_RISING;
  sConfig.IC2Selection = TIM_ICSELECTION_DIRECTTI;
  sConfig.IC2Prescaler = TIM_ICPSC_DIV1;
  sConfig.IC2Filter = 0;
  if (HAL_TIM_Encoder_Init(&htim2, &sConfig) != HAL_OK)
  {
    Error_Handler();
  }
  sMasterConfig.MasterOutputTrigger = TIM_TRGO_RESET;
  sMasterConfig.MasterSlaveMode = TIM_MASTERSLAVEMODE_DISABLE;
  if (HAL_TIMEx_MasterConfigSynchronization(&htim2, &sMasterConfig) != HAL_OK)
  {
    Error_Handler();
  }

}

static void MX_TIM3_Init(void)
{

  TIM_Encoder_InitTypeDef sConfig = {0};
  TIM_MasterConfigTypeDef sMasterConfig = {0};

  htim3.Instance = TIM3;
  htim3.Init.Prescaler = 0;
  htim3.Init.CounterMode = TIM_COUNTERMODE_UP;
  htim3.Init.Period = 4095;
  htim3.Init.ClockDivision = TIM_CLOCKDIVISION_DIV1;
  htim3.Init.AutoReloadPreload = TIM_AUTORELOAD_PRELOAD_DISABLE;
  sConfig.EncoderMode = TIM_ENCODERMODE_TI1;
  sConfig.IC1Polarity = TIM_ICPOLARITY_RISING;
  sConfig.IC1Selection = TIM_ICSELECTION_DIRECTTI;
  sConfig.IC1Prescaler = TIM_ICPSC_DIV1;
  sConfig.IC1Filter = 0;
  sConfig.IC2Polarity = TIM_ICPOLARITY_RISING;
  sConfig.IC2Selection = TIM_ICSELECTION_DIRECTTI;
  sConfig.IC2Prescaler = TIM_ICPSC_DIV1;
  sConfig.IC2Filter = 0;
  if (HAL_TIM_Encoder_Init(&htim3, &sConfig) != HAL_OK)
  {
    Error_Handler();
  }
  sMasterConfig.MasterOutputTrigger = TIM_TRGO_RESET;
  sMasterConfig.MasterSlaveMode = TIM_MASTERSLAVEMODE_DISABLE;
  if (HAL_TIMEx_MasterConfigSynchronization(&htim3, &sMasterConfig) != HAL_OK)
  {
    Error_Handler();
  }

}

static void MX_TIM4_Init(void)
{

  TIM_MasterConfigTypeDef sMasterConfig = {0};
  TIM_OC_InitTypeDef sConfigOC = {0};

  htim4.Instance = TIM4;
  htim4.Init.Prescaler = 0;
  htim4.Init.CounterMode = TIM_COUNTERMODE_UP;
  htim4.Init.Period = 149;
  htim4.Init.ClockDivision = TIM_CLOCKDIVISION_DIV1;
  htim4.Init.AutoReloadPreload = TIM_AUTORELOAD_PRELOAD_DISABLE;
  if (HAL_TIM_PWM_Init(&htim4) != HAL_OK)
  {
    Error_Handler();
  }
  sMasterConfig.MasterOutputTrigger = TIM_TRGO_RESET;
  sMasterConfig.MasterSlaveMode = TIM_MASTERSLAVEMODE_DISABLE;
  if (HAL_TIMEx_MasterConfigSynchronization(&htim4, &sMasterConfig) != HAL_OK)
  {
    Error_Handler();
  }
  sConfigOC.OCMode = TIM_OCMODE_PWM1;
  sConfigOC.Pulse = 0;
  sConfigOC.OCPolarity = TIM_OCPOLARITY_HIGH;
  sConfigOC.OCFastMode = TIM_OCFAST_DISABLE;
  if (HAL_TIM_PWM_ConfigChannel(&htim4, &sConfigOC, TIM_CHANNEL_2) != HAL_OK)
  {
    Error_Handler();
  }
  HAL_TIM_MspPostInit(&htim4);

}

static void MX_TIM6_Init(void)
{

  TIM_MasterConfigTypeDef sMasterConfig = {0};

  htim6.Instance = TIM6;
  htim6.Init.Prescaler = 9999;
  htim6.Init.CounterMode = TIM_COUNTERMODE_UP;
  htim6.Init.Period = 9999;
  htim6.Init.AutoReloadPreload = TIM_AUTORELOAD_PRELOAD_DISABLE;
  if (HAL_TIM_Base_Init(&htim6) != HAL_OK)
  {
    Error_Handler();
  }
  sMasterConfig.MasterOutputTrigger = TIM_TRGO_RESET;
  sMasterConfig.MasterSlaveMode = TIM_MASTERSLAVEMODE_DISABLE;
  if (HAL_TIMEx_MasterConfigSynchronization(&htim6, &sMasterConfig) != HAL_OK)
  {
    Error_Handler();
  }

}

static void MX_TIM7_Init(void)
{

  TIM_MasterConfigTypeDef sMasterConfig = {0};

  htim7.Instance = TIM7;
  htim7.Init.Prescaler = 9900;
  htim7.Init.CounterMode = TIM_COUNTERMODE_UP;
  htim7.Init.Period = 999;
  htim7.Init.AutoReloadPreload = TIM_AUTORELOAD_PRELOAD_DISABLE;
  if (HAL_TIM_Base_Init(&htim7) != HAL_OK)
  {
    Error_Handler();
  }
  sMasterConfig.MasterOutputTrigger = TIM_TRGO_RESET;
  sMasterConfig.MasterSlaveMode = TIM_MASTERSLAVEMODE_DISABLE;
  if (HAL_TIMEx_MasterConfigSynchronization(&htim7, &sMasterConfig) != HAL_OK)
  {
    Error_Handler();
  }

}

static void MX_TIM8_Init(void)
{

  TIM_MasterConfigTypeDef sMasterConfig = {0};
  TIM_OC_InitTypeDef sConfigOC = {0};
  TIM_BreakDeadTimeConfigTypeDef sBreakDeadTimeConfig = {0};

  htim8.Instance = TIM8;
  htim8.Init.Prescaler = 0;
  htim8.Init.CounterMode = TIM_COUNTERMODE_UP;
  htim8.Init.Period = 2499;
  htim8.Init.ClockDivision = TIM_CLOCKDIVISION_DIV1;
  htim8.Init.RepetitionCounter = 0;
  htim8.Init.AutoReloadPreload = TIM_AUTORELOAD_PRELOAD_DISABLE;
  if (HAL_TIM_PWM_Init(&htim8) != HAL_OK)
  {
    Error_Handler();
  }
  sMasterConfig.MasterOutputTrigger = TIM_TRGO_RESET;
  sMasterConfig.MasterOutputTrigger2 = TIM_TRGO2_RESET;
  sMasterConfig.MasterSlaveMode = TIM_MASTERSLAVEMODE_DISABLE;
  if (HAL_TIMEx_MasterConfigSynchronization(&htim8, &sMasterConfig) != HAL_OK)
  {
    Error_Handler();
  }
  sConfigOC.OCMode = TIM_OCMODE_PWM1;
  sConfigOC.Pulse = 0;
  sConfigOC.OCPolarity = TIM_OCPOLARITY_HIGH;
  sConfigOC.OCNPolarity = TIM_OCNPOLARITY_HIGH;
  sConfigOC.OCFastMode = TIM_OCFAST_DISABLE;
  sConfigOC.OCIdleState = TIM_OCIDLESTATE_RESET;
  sConfigOC.OCNIdleState = TIM_OCNIDLESTATE_RESET;
  if (HAL_TIM_PWM_ConfigChannel(&htim8, &sConfigOC, TIM_CHANNEL_1) != HAL_OK)
  {
    Error_Handler();
  }
  if (HAL_TIM_PWM_ConfigChannel(&htim8, &sConfigOC, TIM_CHANNEL_2) != HAL_OK)
  {
    Error_Handler();
  }
  if (HAL_TIM_PWM_ConfigChannel(&htim8, &sConfigOC, TIM_CHANNEL_3) != HAL_OK)
  {
    Error_Handler();
  }
  sBreakDeadTimeConfig.OffStateRunMode = TIM_OSSR_DISABLE;
  sBreakDeadTimeConfig.OffStateIDLEMode = TIM_OSSI_DISABLE;
  sBreakDeadTimeConfig.LockLevel = TIM_LOCKLEVEL_OFF;
  sBreakDeadTimeConfig.DeadTime = 0;
  sBreakDeadTimeConfig.BreakState = TIM_BREAK_DISABLE;
  sBreakDeadTimeConfig.BreakPolarity = TIM_BREAKPOLARITY_HIGH;
  sBreakDeadTimeConfig.BreakFilter = 0;
  sBreakDeadTimeConfig.BreakAFMode = TIM_BREAK_AFMODE_INPUT;
  sBreakDeadTimeConfig.Break2State = TIM_BREAK2_DISABLE;
  sBreakDeadTimeConfig.Break2Polarity = TIM_BREAK2POLARITY_HIGH;
  sBreakDeadTimeConfig.Break2Filter = 0;
  sBreakDeadTimeConfig.Break2AFMode = TIM_BREAK_AFMODE_INPUT;
  sBreakDeadTimeConfig.AutomaticOutput = TIM_AUTOMATICOUTPUT_DISABLE;
  if (HAL_TIMEx_ConfigBreakDeadTime(&htim8, &sBreakDeadTimeConfig) != HAL_OK)
  {
    Error_Handler();
  }
  HAL_TIM_MspPostInit(&htim8);

}

static void MX_TIM17_Init(void)
{

  htim17.Instance = TIM17;
  htim17.Init.Prescaler = 0;
  htim17.Init.CounterMode = TIM_COUNTERMODE_UP;
  htim17.Init.Period = 65535;
  htim17.Init.ClockDivision = TIM_CLOCKDIVISION_DIV1;
  htim17.Init.RepetitionCounter = 0;
  htim17.Init.AutoReloadPreload = TIM_AUTORELOAD_PRELOAD_DISABLE;
  if (HAL_TIM_Base_Init(&htim17) != HAL_OK)
  {
    Error_Handler();
  }

}

static void MX_USART3_UART_Init(void)
{

  huart3.Instance = USART3;
  huart3.Init.BaudRate = 115200;
  huart3.Init.WordLength = UART_WORDLENGTH_8B;
  huart3.Init.StopBits = UART_STOPBITS_1;
  huart3.Init.Parity = UART_PARITY_NONE;
  huart3.Init.Mode = UART_MODE_TX_RX;
  huart3.Init.HwFlowCtl = UART_HWCONTROL_NONE;
  huart3.Init.OverSampling = UART_OVERSAMPLING_16;
  huart3.Init.OneBitSampling = UART_ONE_BIT_SAMPLE_DISABLE;
  huart3.Init.ClockPrescaler = UART_PRESCALER_DIV1;
  huart3.AdvancedInit.AdvFeatureInit = UART_ADVFEATURE_NO_INIT;
  if (HAL_UART_Init(&huart3) != HAL_OK)
  {
    Error_Handler();
  }
  if (HAL_UARTEx_SetTxFifoThreshold(&huart3, UART_TXFIFO_THRESHOLD_1_8) != HAL_OK)
  {
    Error_Handler();
  }
  if (HAL_UARTEx_SetRxFifoThreshold(&huart3, UART_RXFIFO_THRESHOLD_1_8) != HAL_OK)
  {
    Error_Handler();
  }
  if (HAL_UARTEx_DisableFifoMode(&huart3) != HAL_OK)
  {
    Error_Handler();
  }

}

static void MX_DMA_Init(void)
{

  /* DMA controller clock enable */
  __HAL_RCC_DMAMUX1_CLK_ENABLE();
  __HAL_RCC_DMA1_CLK_ENABLE();

  /* DMA interrupt init */
  /* DMA1_Channel1_IRQn interrupt configuration */
  HAL_NVIC_SetPriority(DMA1_Channel1_IRQn, 0, 0);
  HAL_NVIC_EnableIRQ(DMA1_Channel1_IRQn);
  /* DMA1_Channel2_IRQn interrupt configuration */
  HAL_NVIC_SetPriority(DMA1_Channel2_IRQn, 0, 0);
  HAL_NVIC_EnableIRQ(DMA1_Channel2_IRQn);
  /* DMA1_Channel3_IRQn interrupt configuration */
  HAL_NVIC_SetPriority(DMA1_Channel3_IRQn, 0, 0);
  HAL_NVIC_EnableIRQ(DMA1_Channel3_IRQn);

}

static void MX_GPIO_Init(void)
{
  GPIO_InitTypeDef GPIO_InitStruct = {0};

  /* GPIO Ports Clock Enable */
  __HAL_RCC_GPIOC_CLK_ENABLE();
  __HAL_RCC_GPIOF_CLK_ENABLE();
  __HAL_RCC_GPIOA_CLK_ENABLE();
  __HAL_RCC_GPIOB_CLK_ENABLE();

  /*Configure GPIO pin Output Level */
  HAL_GPIO_WritePin(GPIOC, GPIO_PIN_15, GPIO_PIN_RESET);

  /*Configure GPIO pins : PC14 PC6 */
  GPIO_InitStruct.Pin = GPIO_PIN_14|GPIO_PIN_6;
  GPIO_InitStruct.Mode = GPIO_MODE_INPUT;
  GPIO_InitStruct.Pull = GPIO_NOPULL;
  HAL_GPIO_Init(GPIOC, &GPIO_InitStruct);

  /*Configure GPIO pin : PC15 */
  GPIO_InitStruct.Pin = GPIO_PIN_15;
  GPIO_InitStruct.Mode = GPIO_MODE_OUTPUT_PP;
  GPIO_InitStruct.Pull = GPIO_NOPULL;
  GPIO_InitStruct.Speed = GPIO_SPEED_FREQ_LOW;
  HAL_GPIO_Init(GPIOC, &GPIO_InitStruct);

  /*Configure GPIO pin : PA2 */
  GPIO_InitStruct.Pin = GPIO_PIN_2;
  GPIO_InitStruct.Mode = GPIO_MODE_IT_RISING;
  GPIO_InitStruct.Pull = GPIO_NOPULL;
  HAL_GPIO_Init(GPIOA, &GPIO_InitStruct);

  /*Configure GPIO pin : PB3 */
  GPIO_InitStruct.Pin = GPIO_PIN_3;
  GPIO_InitStruct.Mode = GPIO_MODE_IT_RISING;
  GPIO_InitStruct.Pull = GPIO_NOPULL;
  HAL_GPIO_Init(GPIOB, &GPIO_InitStruct);

  /* EXTI interrupt init*/
  HAL_NVIC_SetPriority(EXTI2_IRQn, 0, 0);
  HAL_NVIC_EnableIRQ(EXTI2_IRQn);

  HAL_NVIC_SetPriority(EXTI3_IRQn, 0, 0);
  HAL_NVIC_EnableIRQ(EXTI3_IRQn);

}

void Error_Handler(void)
{
  __disable_irq();
  while (1)
  {
  }
}
